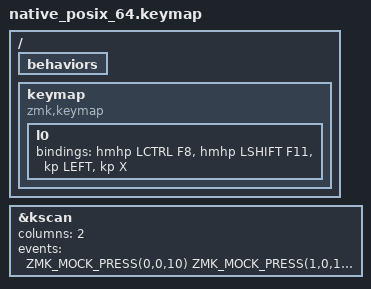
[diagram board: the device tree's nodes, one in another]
// L2 home row mods with the real hmhp (hold-preferred) hold-tap. F8/F11 are mock keys.
// Mock positions: row 0 = F8 (hmhp LCTRL), F11 (hmhp LSHIFT); row 1 = Left, X.
#include <dt-bindings/zmk/keys.h>
#include <behaviors.dtsi>
#include <dt-bindings/zmk/kscan_mock.h>

/ {
    behaviors {
#include "real/hmhp.dtsi"
    };

    keymap {
        compatible = "zmk,keymap";
        l0 { bindings = <&hmhp LCTRL F8 &hmhp LSHIFT F11 &kp LEFT &kp X>; };
    };
};

&kscan {
    columns = <2>;
    events = <
        /* 1: idle, F8 rolled into Left (F8 up before Left up) -> Ctrl+Left */
        ZMK_MOCK_PRESS(0,0,10) ZMK_MOCK_PRESS(1,0,10) ZMK_MOCK_RELEASE(0,0,10) ZMK_MOCK_RELEASE(1,0,300)
        /* 2: same-hand stack: F8, F11, then Left -> Ctrl+Shift+Left */
        ZMK_MOCK_PRESS(0,0,10) ZMK_MOCK_PRESS(0,1,10) ZMK_MOCK_PRESS(1,0,10) ZMK_MOCK_RELEASE(1,0,10)
        ZMK_MOCK_RELEASE(0,1,10) ZMK_MOCK_RELEASE(0,0,300)
        /* 3: x, then F8 rolled into Left within 150 ms -> x, F8, Left (prior-idle tap) */
        ZMK_MOCK_PRESS(1,1,20) ZMK_MOCK_RELEASE(1,1,30) ZMK_MOCK_PRESS(0,0,10) ZMK_MOCK_PRESS(1,0,10)
        ZMK_MOCK_RELEASE(0,0,10) ZMK_MOCK_RELEASE(1,0,300)
        /* 4: F8 tapped alone after idle -> F8 */
        ZMK_MOCK_PRESS(0,0,50) ZMK_MOCK_RELEASE(0,0,300)
    >;
};
